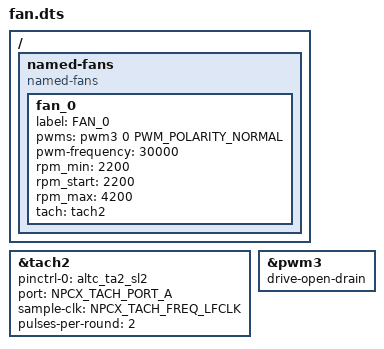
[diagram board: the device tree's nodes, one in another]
/* Copyright 2022 The Chromium OS Authors. All rights reserved.
 * Use of this source code is governed by a BSD-style license that can be
 * found in the LICENSE file.
 */

/ {
	named-fans {
		compatible = "named-fans";

		fan_0 {
			label = "FAN_0";
			pwms = <&pwm3 0 PWM_POLARITY_NORMAL>;
			pwm-frequency = <30000>;
			rpm_min = <2200>;
			rpm_start = <2200>;
			rpm_max = <4200>;
			tach = <&tach2>;
		};
	};
};

/* Tachemeter for fan speed measurement */
&tach2 {
	status = "okay";
	pinctrl-0 = <&altc_ta2_sl2>; /* Use TA2 as input pin */
	port = <NPCX_TACH_PORT_A>; /* port-A is selected */
	sample-clk = <NPCX_TACH_FREQ_LFCLK>; /* Use LFCLK as sampling clock */
	pulses-per-round = <2>; /* number of pulses per round of encoder */
};

&pwm3 {
	status = "okay";
	drive-open-drain;
};
